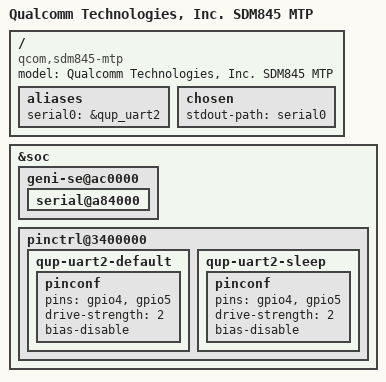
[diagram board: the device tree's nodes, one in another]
// SPDX-License-Identifier: GPL-2.0
/*
 * Copyright (c) 2018, The Linux Foundation. All rights reserved.
 */

/dts-v1/;

#include "sdm845.dtsi"

/ {
	model = "Qualcomm Technologies, Inc. SDM845 MTP";
	compatible = "qcom,sdm845-mtp";

	aliases {
		serial0 = &qup_uart2;
	};

	chosen {
		stdout-path = "serial0";
	};
};

&soc {
	geni-se@ac0000 {
		serial@a84000 {
			status = "okay";
		};
	};

	pinctrl@3400000 {
		qup-uart2-default {
			pinconf {
				pins = "gpio4", "gpio5";
				drive-strength = <2>;
				bias-disable;
			};
		};

		qup-uart2-sleep {
			pinconf {
				pins = "gpio4", "gpio5";
				drive-strength = <2>;
				bias-disable;
			};
		};
	};
};
